# AU302NDF51 register map
File version: 1.0
Registers are 32-bit, access per field, reset 0x0 unless marked. A register's access mark holds for its fields unless they carry their own. Offsets are from the block's base; [hi:lo] are bit positions; {n}, {i} and the like mark numbered series.

## I2C — I2C peripheral interface
Base 0x14100000
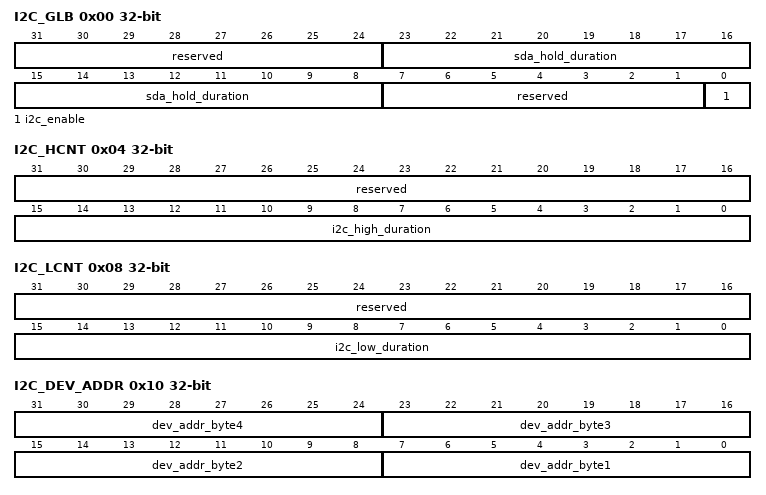
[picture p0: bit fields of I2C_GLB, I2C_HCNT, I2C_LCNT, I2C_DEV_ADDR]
0x00 I2C_GLB — I2C全局配置寄存器
  [31:24] reserved ro — 保留。
  [23:8] sda_hold_duration rw — SDA hold time时长。建议配置为0xa。 注意：只能控制从主机发往从设备的数据的hold time时长。
  [7:1] reserved ro — 保留。
  [0] i2c_enable rw — I2C使能控制。 0：禁止；（此时会清空TX FIFO和RX FIFO） 1：使能。 注意：若出现时序异常，请先禁止控制器，然后再使能，以防TX FIFO和RX FIFO有上次操作的残留数据。
0x04 I2C_HCNT — I2C高电平时长寄存器
  [31:16] reserved ro — 保留。
  [15:0] i2c_high_duration rw — SCL 高电平时长。 建议在标准模式下为SCL周期的1/2，快速模式下为SCL周期的0.36。 标准模式下： i2c_high_duration = (FI2C_CLK/FSCL) x 0.5 快速模式下： i2c_high_duration = (FI2C_CLK/FSCL) x 0.36 (FSCL为SCL总线的频率) 以参考时钟为100MHz且工作在快速模式下(FSCL = 400kHz)为例，i2c_high_duration =(100MHz / 400kHz) x 0.36=90。
0x08 I2C_LCNT — I2C低电平时长寄存器
  [31:16] reserved ro — 保留。
  [15:0] i2c_low_duration rw — SCL低电平时长。 建议在标准模式下为SCL周期的1/2，快速模式下为SCL周期的0.64。 标准模式下： i2c_low_duration = (Fpclk_i2c/FSCL) x 0.5 快速模式下： i2c_low_duration = (Fpclk_i2c/FSCL) x 0.64 (FSCL为SCL总线的频率) 以参考时钟为100MHz且工作在快速模式下(FSCL = 400 kHz)为例，i2c_low_duration=(100MHz / 400kHz) x 0.64=160。
0x10 I2C_DEV_ADDR rw — I2C器件地址寄存器
  [8n-1:8n-8] dev_addr_byte{n} (n=1..4) — 器件地址字节{n}。
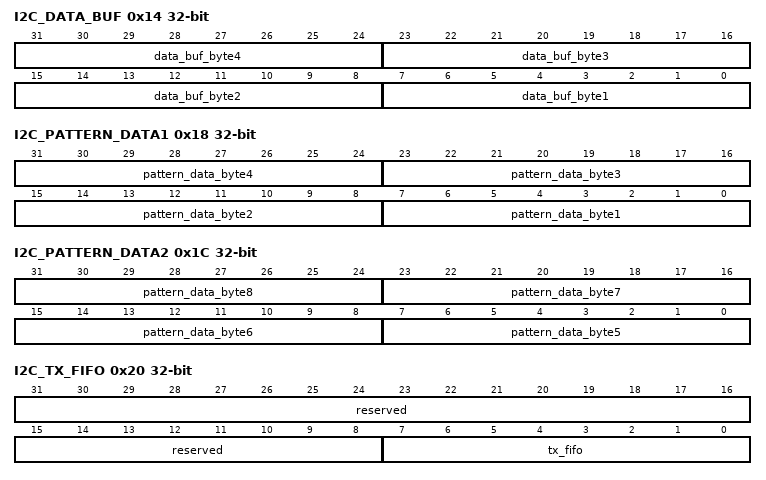
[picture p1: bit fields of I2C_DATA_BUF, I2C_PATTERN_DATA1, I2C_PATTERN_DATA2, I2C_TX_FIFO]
0x14 I2C_DATA_BUF rw — I2C数据buf寄存器
  [8n-1:8n-8] data_buf_byte{n} (n=1..4) — 数据buf字节{n}。
0x18 I2C_PATTERN_DATA1 rw — I2C PATTERN数据寄存器1
  [8n-1:8n-8] pattern_data_byte{n} (n=1..4) — PATTERN数据字节{n}。
0x1C I2C_PATTERN_DATA2 rw — I2C PATTERN数据寄存器2
  [8n-33:8n-40] pattern_data_byte{n} (n=5..8) — PATTERN数据字节{n}。
0x20 I2C_TX_FIFO — I2C TX FIFO 数据寄存器
  [31:8] reserved ro — 保留。
  [7:0] tx_fifo wo — TX FIFO入口。 写入的数据是待发送出去的数据。
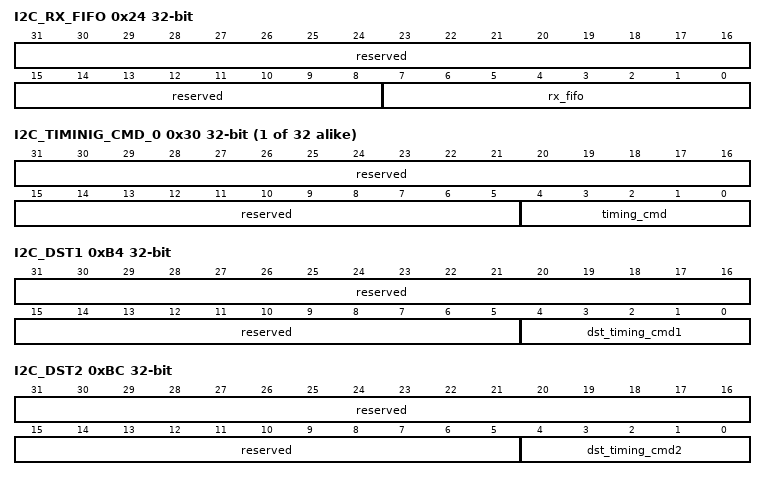
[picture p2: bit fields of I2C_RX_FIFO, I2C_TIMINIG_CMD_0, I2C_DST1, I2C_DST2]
0x24 I2C_RX_FIFO ro — I2C RX FIFO 数据寄存器
  [31:8] reserved — 保留。
  [7:0] rx_fifo — RX FIFO出口。 读出的数据是I2C总线上收到的数据。
{0x30+4i} I2C_TIMINIG_CMD_{i} (i=0..31) — I2C时序命令寄存器
  [31:5] reserved ro — 保留。
  [4:0] timing_cmd rw — 时序命令。n = 0，1，2，…31 0x00：EXIT（结束，用于逻辑退出）； 0x01：S（总线START）； 0x02：WDA4（发送dev_addr_byte4）； 0x03：WDA3（发送dev_addr_byte3）； 0x04：WDA2（发送dev_addr_byte2）； 0x05：WDA1（发送dev_addr_byte1）； 0x06：WDB4（发送data_buf_byte4）； 0x07：WDB3（发送data_buf_byte3）； 0x08：WDB2（发送data_buf_byte2）； 0x09：WDB1（发送data_buf_byte1）； 0x0A：WPD8（发送pattern_data_byte8）； 0x0B：WPD7（发送pattern_data_byte7）； 0x0C：WPD6（发送pattern_data_byte6）； 0x0D：WPD5（发送pattern_data_byte5）； 0x0E：WPD4（发送pattern_data_byte4）； 0x0F：WPD3（发送pattern_data_byte3）； 0x10：WPD2（发送pattern_data_byte2）； 0x11：WPD1（发送pattern_data_byte1）； 0x12：RD（接收1字节数据）； 0x13：RACK（接收低电平应答）； 0x14：RNACK（接收高电平非应答）； 0x15：RNC（接收应答，高低电平都无所谓）； 0x16：SACK（发送低电平应答）； 0x17：SNACK（发送高电平非应答）； 0x18：JMPN1（有限次数跳转，目的由I2C_DST1寄存器指出，次数由I2C_LOOP1寄存器指出）； 0x19：JMPN2（有限次数跳转，目的由I2C_DST2寄存器指出，次数由I2C_LOOP2寄存器指出）； 0x1A：JMPN3（有限次数跳转，目的由I2C_DST3寄存器指出，次数由I2C_LOOP3寄存器指出）； 0x1B：UNDEF（未定义）； 0x1C：UNDEF（未定义）； 0x1D：UDB1（从TX FIFO 更新数据到 data_buf_byte1）； 0x1E：SR（总线repeated START）； 0x1F：P（总线STOP）。 注意： 执行UDB1命令时，若TX FIFO为空，则控制器会等待直到TX FIFO有数据；等待期间控制器不会改变I2C总线的状态。 执行RD命令时，若RX FIFO满了，则控制器会等待直到RX FIFO有空位；等待期间控制器不会改变I2C总线的状态。
{0xA8+8i} I2C_LOOP{i} rw (i=1..3) — I2C循环次数寄存器{i}
  [31:0] loop_num{i} — 指定循环次数。
0xB4 I2C_DST1 — I2C跳转目的寄存器1
  [31:5] reserved ro — 保留。
  [4:0] dst_timing_cmd1 rw — 指定跳转到哪个时序命令寄存器。
0xBC I2C_DST2 — I2C跳转目的寄存器2
  [31:5] reserved ro — 保留
  [4:0] dst_timing_cmd2 rw — 指定跳转到哪个时序命令寄存器
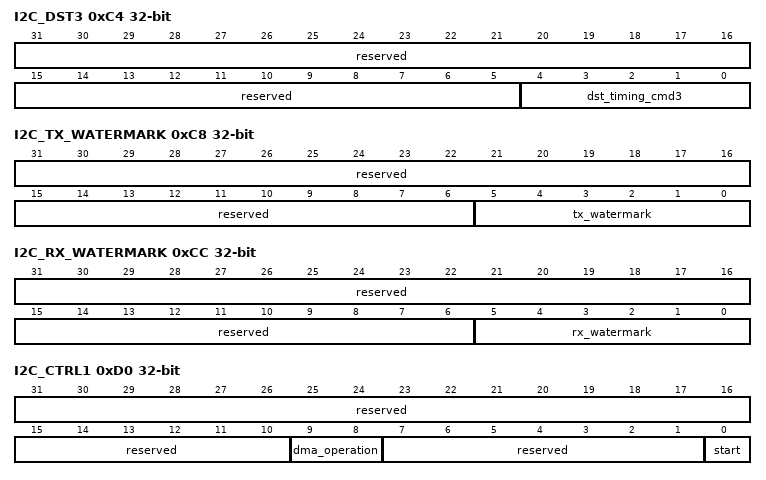
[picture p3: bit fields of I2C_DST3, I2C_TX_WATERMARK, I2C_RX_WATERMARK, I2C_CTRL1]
0xC4 I2C_DST3 — I2C跳转目的寄存器3
  [31:5] reserved ro — 保留。
  [4:0] dst_timing_cmd3 rw — 指定跳转到哪个时序命令寄存器。
0xC8 I2C_TX_WATERMARK — I2C TX FIFO水线寄存器
  [31:6] reserved ro — 保留。
  [5:0] tx_watermark rw — TX FIFO水线。当TX FIFO里的数据数目比tx_watermark小时，tx_lt_watermark_raw原始中断会被置1。
0xCC I2C_RX_WATERMARK — I2C RX FIFO水线寄存器
  [31:6] reserved ro — 保留。
  [5:0] rx_watermark rw — RX FIFO水线。当RX FIFO里的数据数目比rx_watermark大时，rx_gt_watermark_raw原始中断会被置1。
0xD0 I2C_CTRL1 — I2C控制寄存器1
  [31:10] reserved ro — 保留。
  [9:8] dma_operation rw — DMA操作控制。 00：非DMA方式； 01：保留； 10：DMA写方式； 11：DMA读方式。
  [7:1] reserved ro — 保留。
  [0] start rw — 启动控制。写1会启动控制器内部的状态机去执行时序命令序列，执行完毕或者异常后逻辑会反向把此位清0。 0：不启动； 1：启动。
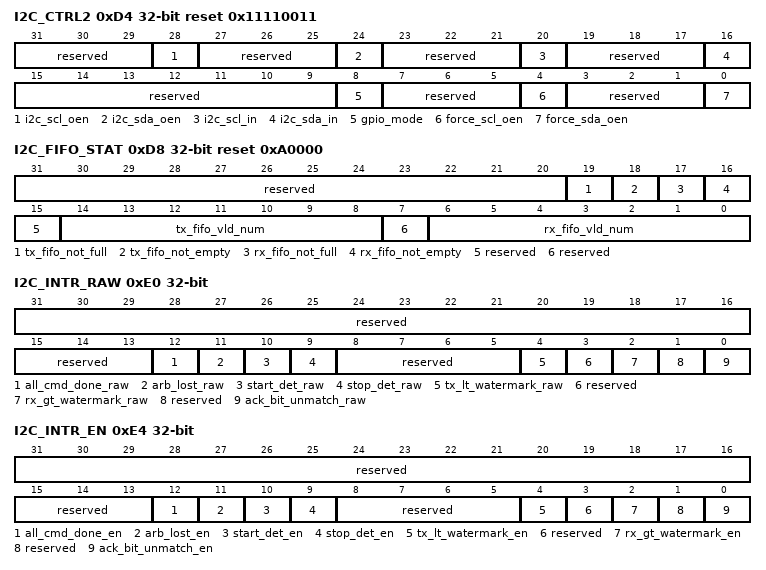
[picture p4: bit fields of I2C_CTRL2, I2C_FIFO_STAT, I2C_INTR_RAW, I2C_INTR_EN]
0xD4 I2C_CTRL2 reset 0x11110011 — I2C控制寄存器2
  [31:29] reserved ro — 保留。
  [28] i2c_scl_oen ro — 监测内部I2C的SDA输出电平。 0：SDA输出低电平； 1：SDA输出高电平。
  [27:25] reserved ro — 保留。
  [24] i2c_sda_oen ro — 监测内部I2C的SCL输出电平。 0：SCL输出低电平； 1：SCL输出高电平。
  [23:21] reserved ro — 保留。
  [20] i2c_scl_in ro — 监测外部I2C总线SCL的电平。 0：总线上SCL为低电平； 1：总线上SCL为高电平。
  [19:17] reserved ro — 保留。
  [16] i2c_sda_in ro — 监测外部I2C总线SDA的电平。 0：总线上SDA为低电平； 1：总线上SDA为高电平。
  [15:9] reserved ro — 保留。
  [8] gpio_mode rw — 将I2C的SCL和SDA管脚配置成gpio模式，管脚电平由force_scl_oe_n和force_sda_oe_n决定。 0：禁止； 1：使能。
  [7:5] reserved ro — 保留
  [4] force_scl_oen rw — 在 gpio_mode 有效时控制 SCL 管脚电平。 0： SCL 管脚为低电平； 1： SCL 管脚为高电平。
  [3:1] reserved ro — 保留
  [0] force_sda_oen rw — 在gpio_mode有效时控制SDA管脚电平。 0：SDA管脚为低电平； 1：SDA管脚为高电平。
0xD8 I2C_FIFO_STAT ro reset 0xA0000 — I2C FIFO状态寄存器
  [31:20] reserved — 保留
  [19] tx_fifo_not_full — TX FIFO非满指示。 0：满； 1：非满。
  [18] tx_fifo_not_empty — TX FIFO非空指示。 0：空； 1：非空。
  [17] rx_fifo_not_full — RX FIFO非满指示。 0：满； 1：非满。
  [16] rx_fifo_not_empty — RX FIFO非空指示。 0：空； 1：非空。
  [15] reserved — 保留。
  [14:8] tx_fifo_vld_num — TX FIFO里的有效数目。
  [7] reserved — 保留。
  [6:0] rx_fifo_vld_num — RX FIFO里的有效数目。
0xE0 I2C_INTR_RAW — I2C原始中断寄存器
  [31:13] reserved ro — 保留。
  [12] all_cmd_done_raw rw write-1-clears — 时序命令序列执行到EXIT命令时产生此中断。 0：无中断； 1：有中断。
  [11] arb_lost_raw rw write-1-clears — 仲裁丢失。 0：无中断； 1：有中断。
  [10] start_det_raw rw write-1-clears — 检查到START。 0：无中断； 1：有中断。
  [9] stop_det_raw rw write-1-clears — 检查到STOP。 0：无中断； 1：有中断。
  [8:5] reserved ro — 保留。
  [4] tx_lt_watermark_raw rw write-1-clears — 发送数据时，TX FIFO里的数据数目低于水线。 0：无中断； 1：有中断。
  [3] reserved ro — 保留
  [2] rx_gt_watermark_raw rw write-1-clears — 接收数据时，RX FIFO里的数据数目高于水线。 0：无中断； 1：有中断。
  [1] reserved ro — 保留
  [0] ack_bit_unmatch_raw rw write-1-clears — 应答位不符合预期。 0：无中断； 1：有中断。
0xE4 I2C_INTR_EN — I2C中断使能寄存器
  [31:13] reserved ro — 保留
  [12] all_cmd_done_en rw — all_cmd_done中断使能。 0：不使能； 1：使能。
  [11] arb_lost_en rw — arb_lost中断使能。 0：不使能； 1：使能。
  [10] start_det_en rw — start_det中断使能。 0：不使能； 1：使能。
  [9] stop_det_en rw — stop中断使能。 0：不使能； 1：使能。
  [8:5] reserved ro
  [4] tx_lt_watermark_en rw — tx_lt_watermark中断使能。 0：不使能； 1：使能。
  [3] reserved ro — 保留
  [2] rx_gt_watermark_en rw — rx_gt_watermark中断使能。 0：不使能； 1：使能。
  [1] reserved ro — 保留
  [0] ack_bit_unmatch_en rw — ack_bit_unmatch中断使能。 0：不使能； 1：使能。
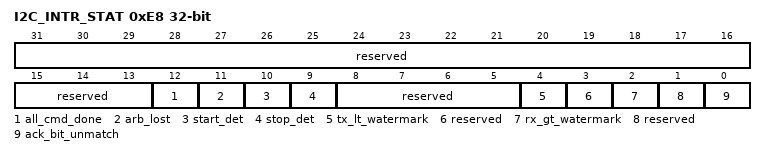
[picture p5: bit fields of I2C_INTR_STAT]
0xE8 I2C_INTR_STAT ro — I2C中断状态寄存器
  [31:13] reserved — 保留
  [12] all_cmd_done — 所有时序命令正常完成。 0：无中断； 1：有中断。
  [11] arb_lost — 仲裁丢失。 0：无中断； 1：有中断。
  [10] start_det — 检查到START。 0：无中断； 1：有中断。
  [9] stop_det — 检查到STOP。 0：无中断； 1：有中断。
  [8:5] reserved — 保留。
  [4] tx_lt_watermark — 发送数据时，TX FIFO里的数据数目低于水线。 0：无中断； 1：有中断。
  [3] reserved — 保留
  [2] rx_gt_watermark — 接收数据时，RX FIFO里的数据数目高于水线。 0：无中断； 1：有中断。
  [1] reserved — 保留
  [0] ack_bit_unmatch — 应答位不符合预期。 0：无中断； 1：有中断。
